# CH32V203G6U6 register map
Vendor: WCH; File version: 0.1.0
CPU: QingKe V4B V4B, little endian, no MPU, no FPU, vendor SysTick, 4 interrupt priority bits
Registers are 16-bit, read-write, reset 0x0 unless marked. A register's access mark holds for its fields unless they carry their own. Offsets are from the block's base; [hi:lo] are bit positions.

## RCC — Reset and clock control block
Base 0x40021000
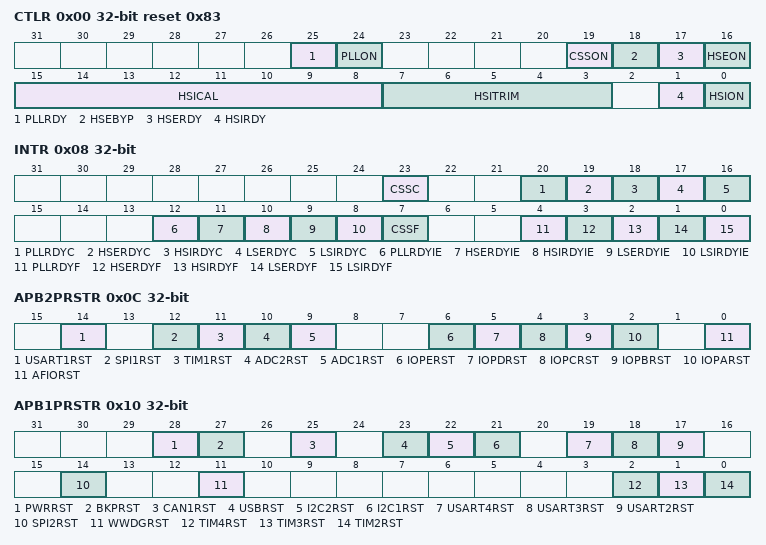
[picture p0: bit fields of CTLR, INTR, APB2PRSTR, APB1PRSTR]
0x00 CTLR 32-bit reset 0x83 — Clock control register
  [25] PLLRDY ro — PLL clock ready flag
  [24] PLLON — PLL enable
  [19] CSSON — Clock Security System enable
  [18] HSEBYP — External High Speed clock Bypass
  [17] HSERDY ro — External High Speed clock ready flag
  [16] HSEON — External High Speed clock enable
  [15:8] HSICAL ro — Internal High Speed clock Calibration
  [7:3] HSITRIM — Internal High Speed clock trimming
  [1] HSIRDY ro — Internal High Speed clock ready flag
  [0] HSION — Internal High Speed clock enable
0x04 CFGR0 32-bit — Clock configuration register (RCC_CFGR0)
  [26] MCO_SYSCLK
  [26:25] MCO_HSE
  [26:24] MCO
  [26:24] MCO_PLL
  [22] USBPRE
  [21:18] PLLMULL
  [17] PLLXTPRE — HSE divider for PLL entry
  [16] PLLSRC — PLL entry clock source
  [16] PLLSRC_HSE
  [15] ADCPRE_DIV6
  [15:14] ADCPRE — ADC prescaler
  [14] ADCPRE_DIV4
  [15:14] ADCPRE_DIV8
  [13] PPRE2_DIV2
  [13:12] PPRE2_DIV8
  [13:11] PPRE2 — APB High speed prescaler (APB2)
  [13:11] PPRE2_DIV16
  [10] PPRE1_DIV2
  [10:9] PPRE1_DIV8
  [10:8] PPRE1 — APB Low speed prescaler (APB1)
  [10:8] PPRE1_DIV16
  [7] HPRE_DIV2
  [7:6] HPRE_DIV64
  [7:5] HPRE_DIV256
  [7:4] HPRE — AHB prescaler
  [7:4] HPRE_DIV512
  [3] SWS_PLL
  [3:2] SWS ro — System Clock Switch Status
  [2] SWS_HSE
  [1] SW_PLL
  [1:0] SW — System clock Switch
  [0] SW_HSE
0x08 INTR 32-bit — Clock interrupt register (RCC_INTR)
  [23] CSSC wo — Clock security system interrupt clear
  [20] PLLRDYC wo — PLL Ready Interrupt Clear
  [19] HSERDYC wo — HSE Ready Interrupt Clear
  [18] HSIRDYC wo — HSI Ready Interrupt Clear
  [17] LSERDYC wo — LSE Ready Interrupt Clear
  [16] LSIRDYC wo — LSI Ready Interrupt Clear
  [12] PLLRDYIE — PLL Ready Interrupt Enable
  [11] HSERDYIE — HSE Ready Interrupt Enable
  [10] HSIRDYIE — HSI Ready Interrupt Enable
  [9] LSERDYIE — LSE Ready Interrupt Enable
  [8] LSIRDYIE — LSI Ready Interrupt Enable
  [7] CSSF ro — Clock Security System Interrupt flag
  [4] PLLRDYF ro — PLL Ready Interrupt flag
  [3] HSERDYF ro — HSE Ready Interrupt flag
  [2] HSIRDYF ro — HSI Ready Interrupt flag
  [1] LSERDYF ro — LSE Ready Interrupt flag
  [0] LSIRDYF ro — LSI Ready Interrupt flag
0x0C APB2PRSTR 32-bit — APB2 peripheral reset register (RCC_APB2PRSTR)
  [14] USART1RST — USART1 reset
  [12] SPI1RST — SPI 1 reset
  [11] TIM1RST — TIM1 timer reset
  [10] ADC2RST — ADC 2 interface reset
  [9] ADC1RST — ADC 1 interface reset
  [6] IOPERST — IO port E reset
  [5] IOPDRST — IO port D reset
  [4] IOPCRST — IO port C reset
  [3] IOPBRST — IO port B reset
  [2] IOPARST — IO port A reset
  [0] AFIORST — Alternate function I/O reset
0x10 APB1PRSTR 32-bit — APB1 peripheral reset register (RCC_APB1PRSTR)
  [28] PWRRST — Power interface reset
  [27] BKPRST — Backup interface reset
  [25] CAN1RST — CAN1 reset
  [23] USBRST
  [22] I2C2RST — I2C2 reset
  [21] I2C1RST — I2C1 reset
  [19] USART4RST — USART 4 reset
  [18] USART3RST — USART 3 reset
  [17] USART2RST — USART 2 reset
  [14] SPI2RST — SPI2 reset
  [11] WWDGRST — Window watchdog reset
  [2] TIM4RST — Timer 4 reset
  [1] TIM3RST — Timer 3 reset
  [0] TIM2RST — Timer 2 reset
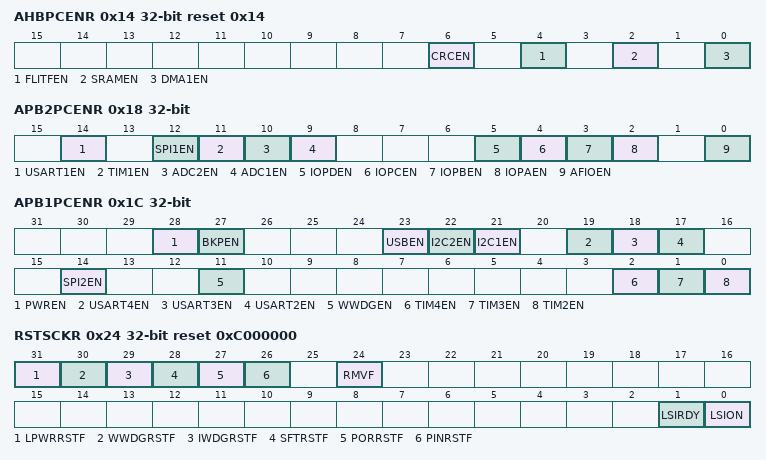
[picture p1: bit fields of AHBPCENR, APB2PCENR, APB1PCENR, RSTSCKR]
0x14 AHBPCENR 32-bit reset 0x14 — AHB Peripheral Clock enable register (RCC_AHBPCENR)
  [6] CRCEN — CRC clock enable
  [4] FLITFEN — FLITF clock enable
  [2] SRAMEN — SRAM interface clock enable
  [0] DMA1EN — DMA clock enable
0x18 APB2PCENR 32-bit — APB2 peripheral clock enable register (RCC_APB2PCENR)
  [14] USART1EN — USART1 clock enable
  [12] SPI1EN — SPI 1 clock enable
  [11] TIM1EN — TIM1 Timer clock enable
  [10] ADC2EN — ADC 2 interface clock enable
  [9] ADC1EN — ADC1 interface clock enable
  [5] IOPDEN — I/O port D clock enable
  [4] IOPCEN — I/O port C clock enable
  [3] IOPBEN — I/O port B clock enable
  [2] IOPAEN — I/O port A clock enable
  [0] AFIOEN — Alternate function I/O clock enable
0x1C APB1PCENR 32-bit — APB1 peripheral clock enable register (RCC_APB1PCENR)
  [28] PWREN — Power interface clock enable
  [27] BKPEN — Backup interface clock enable
  [23] USBEN
  [22] I2C2EN — I2C 2 clock enable
  [21] I2C1EN — I2C 1 clock enable
  [19] USART4EN — USART 4 clock enable
  [18] USART3EN — USART 3 clock enable
  [17] USART2EN — USART 2 clock enable
  [14] SPI2EN — SPI2 clock enable
  [11] WWDGEN — Window watchdog clock enable
  [2] TIM4EN — Timer 4 clock enable
  [1] TIM3EN — Timer 3 clock enable
  [0] TIM2EN — Timer 2 clock enable
0x20 BDCTLR 32-bit — Backup domain control register (RCC_BDCTLR)
  [16] BDRST — Backup domain software reset
  [15] RTCEN — RTC clock enable
  [9] RTCSEL_LSI
  [9:8] RTCSEL — RTC clock source selection
  [8] RTCSEL_LSE
  [9:8] RTCSEL_HSE
  [2] LSEBYP — External Low Speed oscillator bypass
  [1] LSERDY ro — External Low Speed oscillator ready
  [0] LSEON — External Low Speed oscillator enable
0x24 RSTSCKR 32-bit reset 0xC000000 — Control/status register (RCC_RSTSCKR)
  [31] LPWRRSTF — Low-power reset flag
  [30] WWDGRSTF — Window watchdog reset flag
  [29] IWDGRSTF — Independent watchdog reset flag
  [28] SFTRSTF — Software reset flag
  [27] PORRSTF — POR/PDR reset flag
  [26] PINRSTF — PIN reset flag
  [24] RMVF — Remove reset flag
  [1] LSIRDY ro — Internal low speed oscillator ready
  [0] LSION — Internal low speed oscillator enable
0x28 AHBRSTR 32-bit — AHB reset register (RCC_APHBRSTR)
0x2C CFGR2 32-bit — Clock configuration register2 (RCC_CFGR2)
